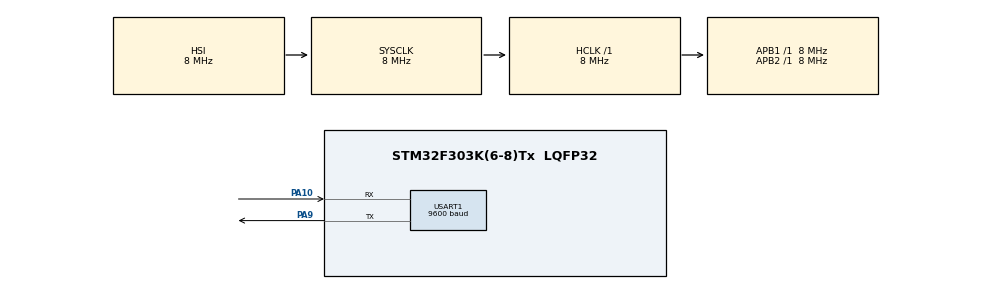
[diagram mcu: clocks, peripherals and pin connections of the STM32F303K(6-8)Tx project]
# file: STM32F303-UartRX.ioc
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Mcu.Family=STM32F3
Mcu.Name=STM32F303K(6-8)Tx
Mcu.Package=LQFP32
NVIC.PriorityGroup=NVIC_PRIORITYGROUP_4
NVIC.USART1_IRQn=true\:0\:0\:false\:false\:true
PA10.Mode=Asynchronous
PA10.Signal=USART1_RX
PA13.GPIO_Label=SWDIO
PA13.Signal=SYS_JTMS-SWDIO
PA14.GPIO_Label=SWCLK
PA14.Signal=SYS_JTCK-SWCLK
PA15.GPIO_Label=VCP_RX
PA15.Signal=USART2_RX
PA2.GPIO_Label=VCP_TX
PA2.Signal=USART2_TX
PA9.Mode=Asynchronous
PA9.Signal=USART1_TX
PF0\ /\ OSC_IN.GPIO_Label=MCO
PF0\ /\ OSC_IN.Signal=RCC_OSC_IN
ProjectManager.HeapSize=0x200
ProjectManager.StackSize=0x400
ProjectManager.TargetToolchain=SW4STM32
RCC.AHBFreq_Value=8000000
RCC.APB1Freq_Value=8000000
RCC.APB2Freq_Value=8000000
RCC.CortexFreq_Value=8000000
RCC.HSE_VALUE=8000000
RCC.HSI_VALUE=8000000
RCC.SYSCLKFreq_VALUE=8000000
USART1.BaudRate=9600
USART1.WordLength=UART_WORDLENGTH_8B
board=NUCLEO-F303K8

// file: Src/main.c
/**
  ******************************************************************************
  * File Name          : main.c
  * Description        : Main program body
  ******************************************************************************
  *
  * COPYRIGHT(c) 2017 STMicroelectronics
  *
  * Redistribution and use in source and binary forms, with or without modification,
  * are permitted provided that the following conditions are met:
  *   1. Redistributions of source code must retain the above copyright notice,
  *      this list of conditions and the following disclaimer.
  *   2. Redistributions in binary form must reproduce the above copyright notice,
  *      this list of conditions and the following disclaimer in the documentation
  *      and/or other materials provided with the distribution.
  *   3. Neither the name of STMicroelectronics nor the names of its contributors
  *      may be used to endorse or promote products derived from this software
  *      without specific prior written permission.
  *
  * THIS SOFTWARE IS PROVIDED BY THE COPYRIGHT HOLDERS AND CONTRIBUTORS "AS IS"
  * AND ANY EXPRESS OR IMPLIED WARRANTIES, INCLUDING, BUT NOT LIMITED TO, THE
  * IMPLIED WARRANTIES OF MERCHANTABILITY AND FITNESS FOR A PARTICULAR PURPOSE ARE
  * DISCLAIMED. IN NO EVENT SHALL THE COPYRIGHT HOLDER OR CONTRIBUTORS BE LIABLE
  * FOR ANY DIRECT, INDIRECT, INCIDENTAL, SPECIAL, EXEMPLARY, OR CONSEQUENTIAL
  * DAMAGES (INCLUDING, BUT NOT LIMITED TO, PROCUREMENT OF SUBSTITUTE GOODS OR
  * SERVICES; LOSS OF USE, DATA, OR PROFITS; OR BUSINESS INTERRUPTION) HOWEVER
  * CAUSED AND ON ANY THEORY OF LIABILITY, WHETHER IN CONTRACT, STRICT LIABILITY,
  * OR TORT (INCLUDING NEGLIGENCE OR OTHERWISE) ARISING IN ANY WAY OUT OF THE USE
  * OF THIS SOFTWARE, EVEN IF ADVISED OF THE POSSIBILITY OF SUCH DAMAGE.
  *
  ******************************************************************************
  */
#include "main.h"
#include "stm32f3xx_hal.h"

UART_HandleTypeDef huart1;

/* USER CODE BEGIN PV */
/* Private variables ---------------------------------------------------------*/

/* USER CODE END PV */

void SystemClock_Config(void);
void Error_Handler(void);
static void MX_GPIO_Init(void);
static void MX_USART1_UART_Init(void);

/* USER CODE BEGIN PFP */
/* Private function prototypes -----------------------------------------------*/
int _write( int file, char *ptr, int len )
{
  HAL_UART_Transmit(&huart1,(uint8_t*) ptr, len, 1000);
  return len;
}

char UART1_Data;
char UART2_Data;
char RXBUFF=1;
//char UART2_Data;
/* USER CODE END PFP */
void HAL_UART_RxCpltCallback(UART_HandleTypeDef *UartHandle)
{
	//printf("CALL UART! \n");

	if(UartHandle->Instance==USART1){

		  HAL_UART_Receive_IT(&huart1, (uint8_t*) &UART1_Data, 1);
		  printf("%c, %c \n",UART1_Data,RXBUFF);

	}
	else if(UartHandle->Instance==USART2){
		//HAL_UART_Receive_IT(&huart1, (uint8_t*) &UART2_Data, 1);
	}

}
/* USER CODE BEGIN 0 */
//void USART1_IRQHandler(void)
//{
//	}
/* USER CODE END 0 */

int main(void)
{

  /* MCU Configuration----------------------------------------------------------*/

  /* Reset of all peripherals, Initializes the Flash interface and the Systick. */
  HAL_Init();

  /* Configure the system clock */
  SystemClock_Config();

  /* Initialize all configured peripherals */
  MX_GPIO_Init();
  MX_USART1_UART_Init();

  /* USER CODE BEGIN 2 */
  printf("Initialize Success!!\n");
  /* USER CODE END 2 */
//  __HAL_UART_ENABLE_IT(&huart1, UART_IT_RXNE);
//
//  huart1.pRxBuffPtr=(uint8_t *)&UART1_Data;
//  huart1.RxXferCount=1;
//  huart1.Mask=255;
  HAL_UART_Receive_IT(&huart1, (uint8_t*) &UART1_Data, 1);
  /* Infinite loop */
  while (1)
  {
//	  __HAL_UART_ENABLE_IT(&huart1, UART_IT_RXNE);
	  if(huart1.RxState== HAL_UART_STATE_BUSY_RX){
		 // printf("BUSY \n");
	  }
	  else{
		  //printf("READY \n");

	  }
	  HAL_Delay(300);
//	  __HAL_UART_DISABLE_IT(&huart1, UART_IT_RXNE);
  }

}

/** System Clock Configuration
*/
void SystemClock_Config(void)
{

  RCC_OscInitTypeDef RCC_OscInitStruct;
  RCC_ClkInitTypeDef RCC_ClkInitStruct;
  RCC_PeriphCLKInitTypeDef PeriphClkInit;

    /**Initializes the CPU, AHB and APB busses clocks
    */
  RCC_OscInitStruct.OscillatorType = RCC_OSCILLATORTYPE_HSI;
  RCC_OscInitStruct.HSIState = RCC_HSI_ON;
  RCC_OscInitStruct.HSICalibrationValue = 16;
  RCC_OscInitStruct.PLL.PLLState = RCC_PLL_NONE;
  if (HAL_RCC_OscConfig(&RCC_OscInitStruct) != HAL_OK)
  {
    Error_Handler();
  }

    /**Initializes the CPU, AHB and APB busses clocks
    */
  RCC_ClkInitStruct.ClockType = RCC_CLOCKTYPE_HCLK|RCC_CLOCKTYPE_SYSCLK
                              |RCC_CLOCKTYPE_PCLK1|RCC_CLOCKTYPE_PCLK2;
  RCC_ClkInitStruct.SYSCLKSource = RCC_SYSCLKSOURCE_HSI;
  RCC_ClkInitStruct.AHBCLKDivider = RCC_SYSCLK_DIV1;
  RCC_ClkInitStruct.APB1CLKDivider = RCC_HCLK_DIV1;
  RCC_ClkInitStruct.APB2CLKDivider = RCC_HCLK_DIV1;

  if (HAL_RCC_ClockConfig(&RCC_ClkInitStruct, FLASH_LATENCY_0) != HAL_OK)
  {
    Error_Handler();
  }

  PeriphClkInit.PeriphClockSelection = RCC_PERIPHCLK_USART1;
  PeriphClkInit.Usart1ClockSelection = RCC_USART1CLKSOURCE_PCLK1;
  if (HAL_RCCEx_PeriphCLKConfig(&PeriphClkInit) != HAL_OK)
  {
    Error_Handler();
  }

    /**Configure the Systick interrupt time
    */
  HAL_SYSTICK_Config(HAL_RCC_GetHCLKFreq()/1000);

    /**Configure the Systick
    */
  HAL_SYSTICK_CLKSourceConfig(SYSTICK_CLKSOURCE_HCLK);

  /* SysTick_IRQn interrupt configuration */
  HAL_NVIC_SetPriority(SysTick_IRQn, 0, 0);
}

/* USART1 init function */
static void MX_USART1_UART_Init(void)
{

  huart1.Instance = USART1;
  huart1.Init.BaudRate = 9600;
  huart1.Init.WordLength = UART_WORDLENGTH_8B;
  huart1.Init.StopBits = UART_STOPBITS_1;
  huart1.Init.Parity = UART_PARITY_NONE;
  huart1.Init.Mode = UART_MODE_TX_RX;
  huart1.Init.HwFlowCtl = UART_HWCONTROL_NONE;
  huart1.Init.OverSampling = UART_OVERSAMPLING_16;
  huart1.Init.OneBitSampling = UART_ONE_BIT_SAMPLE_DISABLE;
  huart1.AdvancedInit.AdvFeatureInit = UART_ADVFEATURE_NO_INIT;
  if (HAL_UART_Init(&huart1) != HAL_OK)
  {
    Error_Handler();
  }

}

/** Configure pins as
        * Analog
        * Input
        * Output
        * EVENT_OUT
        * EXTI
     PA2   ------> USART2_TX
     PA15   ------> USART2_RX
*/
static void MX_GPIO_Init(void)
{

  GPIO_InitTypeDef GPIO_InitStruct;

  /* GPIO Ports Clock Enable */
  __HAL_RCC_GPIOF_CLK_ENABLE();
  __HAL_RCC_GPIOA_CLK_ENABLE();

  /*Configure GPIO pins : VCP_TX_Pin VCP_RX_Pin */
  GPIO_InitStruct.Pin = VCP_TX_Pin|VCP_RX_Pin;
  GPIO_InitStruct.Mode = GPIO_MODE_AF_PP;
  GPIO_InitStruct.Pull = GPIO_NOPULL;
  GPIO_InitStruct.Speed = GPIO_SPEED_FREQ_HIGH;
  GPIO_InitStruct.Alternate = GPIO_AF7_USART2;
  HAL_GPIO_Init(GPIOA, &GPIO_InitStruct);

}

void Error_Handler(void)
{
  while(1)
  {
  }
}

/************************ (C) COPYRIGHT STMicroelectronics *****END OF FILE****/
